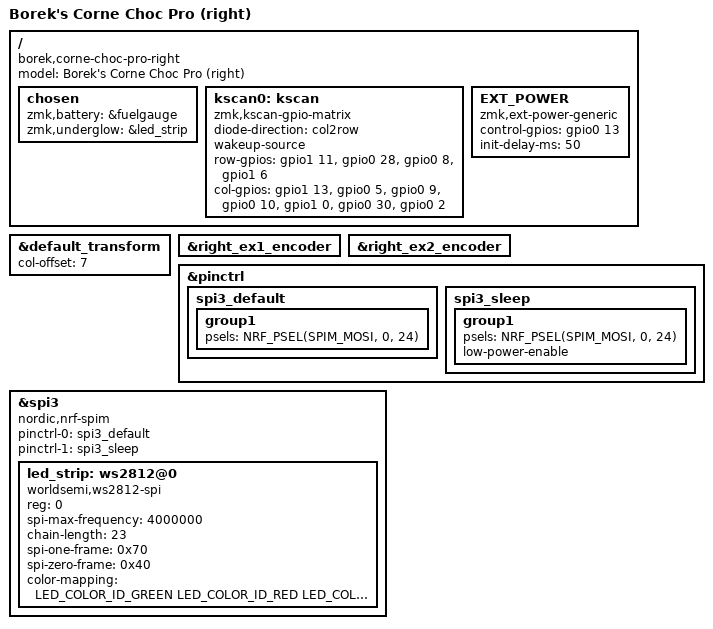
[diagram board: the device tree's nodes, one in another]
/*
 * Copyright (c) 2026 The ZMK Contributors
 *
 * SPDX-License-Identifier: MIT
 */

#include "corne_choc_pro.dtsi"
#include <dt-bindings/led/led.h>

/ {
    model = "Borek's Corne Choc Pro (right)";
    compatible = "borek,corne-choc-pro-right";

    chosen {
        zmk,battery = &fuelgauge;
        zmk,underglow = &led_strip;
    };

    kscan0: kscan {
        compatible = "zmk,kscan-gpio-matrix";
        diode-direction = "col2row";
        wakeup-source;

        row-gpios
            = <&gpio1 11 (GPIO_ACTIVE_HIGH | GPIO_PULL_DOWN)>
            , <&gpio0 28 (GPIO_ACTIVE_HIGH | GPIO_PULL_DOWN)>
            , <&gpio0  8 (GPIO_ACTIVE_HIGH | GPIO_PULL_DOWN)>
            , <&gpio1  6 (GPIO_ACTIVE_HIGH | GPIO_PULL_DOWN)>
            ;
        col-gpios
            = <&gpio1 13 GPIO_ACTIVE_HIGH>
            , <&gpio0  5 GPIO_ACTIVE_HIGH>
            , <&gpio0  9 GPIO_ACTIVE_HIGH>
            , <&gpio0 10 GPIO_ACTIVE_HIGH>
            , <&gpio1  0 GPIO_ACTIVE_HIGH>
            , <&gpio0 30 GPIO_ACTIVE_HIGH>
            , <&gpio0  2 GPIO_ACTIVE_HIGH>
            ;
    };

    // Node name must stay "EXT_POWER" so the saved on/off setting keeps
    // applying across firmware updates.
    EXT_POWER {
        compatible = "zmk,ext-power-generic";
        control-gpios = <&gpio0 13 GPIO_ACTIVE_HIGH>;
        init-delay-ms = <50>;
    };
};

&default_transform {
    col-offset = <7>;
};

&right_ex1_encoder {
    status = "okay";
};

&right_ex2_encoder {
    status = "okay";
};

&pinctrl {
    spi3_default: spi3_default {
        group1 {
            psels = <NRF_PSEL(SPIM_MOSI, 0, 24)>;
        };
    };

    spi3_sleep: spi3_sleep {
        group1 {
            psels = <NRF_PSEL(SPIM_MOSI, 0, 24)>;
            low-power-enable;
        };
    };
};

// RGB underglow, driven over the SPI data line.
&spi3 {
    compatible = "nordic,nrf-spim";
    status = "okay";

    pinctrl-0 = <&spi3_default>;
    pinctrl-1 = <&spi3_sleep>;
    pinctrl-names = "default", "sleep";

    led_strip: ws2812@0 {
        compatible = "worldsemi,ws2812-spi";

        /* SPI */
        reg = <0>; /* ignored, but necessary for SPI bindings */
        spi-max-frequency = <4000000>;

        /* WS2812 */
        chain-length = <23>; /* number of LEDs */
        spi-one-frame = <0x70>;
        spi-zero-frame = <0x40>;
        color-mapping = <LED_COLOR_ID_GREEN LED_COLOR_ID_RED LED_COLOR_ID_BLUE>;
    };
};
